# WE2_S_NS register map
Vendor: ARM Ltd.; Series: ARMv8.1-M Mainline; File version: 1.0
CPU: CM55 r1p1, little endian, MPU, FPU, double-precision FPU, DSP, VTOR, 3 interrupt priority bits
Registers are 32-bit, read-write, reset 0x0 unless marked. A register's access mark holds for its fields unless they carry their own. Offsets are from the block's base; [hi:lo] are bit positions; {n}, {i} and the like mark numbered series.

## SYS_ITM
Base 0xE0000000
{0x0+4i} STIM{i} reset 0x2 (i=0..31) — ITM Stimulus Port Registers {i}
0xE00 TER — ITM Trace Enable Register
0xE40 TPR — ITM Trace Privilege Register
0xE80 TCR — ITM Trace Control Register
0xEF0 INT_ITREAD ro — Integration Read Register
0xEF8 INT_ITWRITE wo — Integration Write Register
0xF00 ITCTRL wo — ITM Integration Mode Control Register
0xFBC DEVARCH ro reset 0x47701A01 — ITM CoreSight Device Architecture Register
0xFCC DEVTYPE wo reset 0x43 — ITM CoreSight Device Type Register
0xFD0 PIDR4 ro reset 0x4 — ITM Peripheral identification registers 4
{0xFC0+4i} PIDR{i} ro (i=5..7) — ITM Peripheral identification registers {i}
0xFE0 PIDR0 ro reset 0xD2 — ITM Peripheral identification registers 0
0xFE4 PIDR1 ro reset 0xBD — ITM Peripheral identification registers 1
0xFE8 PIDR2 ro reset 0xB — ITM Peripheral identification registers 2
0xFEC PIDR3 ro — ITM Peripheral identification registers 3
0xFF0 CIDR0 ro reset 0xD — ITM Component identification register 0
0xFF4 CIDR1 ro reset 0x90 — ITM Component identification register 1
0xFF8 CIDR2 ro reset 0x5 — ITM Component identification register 2
0xFFC CIDR3 ro reset 0xB1 — ITM Component identification register 3

## SYS_DWT — Data Watchpoint and Trace (DWT) registers
Base 0xE0001000
0x00 DWT_CTRL — DWT Control Register
0x04 DWT_CYCCNT — DWT Cycle Count Register
0x08 DWT_CPICNT — DWT CPI Count Register
0x0C DWT_EXCCNT — DWT Exception Overhead Count Register
0x10 DWT_SLEEPCNT — DWT Sleep Count Register
0x14 DWT_LSUCNT — DWT LSU Count Register
0x18 DWT_FOLDCNT — DWT Folded-instruction Count Register
0x1C DWT_PCSR ro — DWT Program Counter Sample Register

## SYS_BPU — Direct Cache Access Registers
Base 0xE0002000
0x00 FP_CTRL — Flash Patch Control Register
0x04 FP_REMAP — Flash Patch Remap. This register is not implemented
{0x8+4i} FP_COMP{i} (i=0..7) — Flash Patch Comparator Register {i}

## SYS_NVIC_STIR — Software Interrupt Generation register
Base 0xE000EF00
Same registers: SYS_NVIC_STIR_NS 0xE002EF00
0x00 STIR wo — Software Interrupt Generation register

## SYS_DCB
Base 0xE000EDF0
Same registers: SYS_DCB_NS 0xE002EDF0
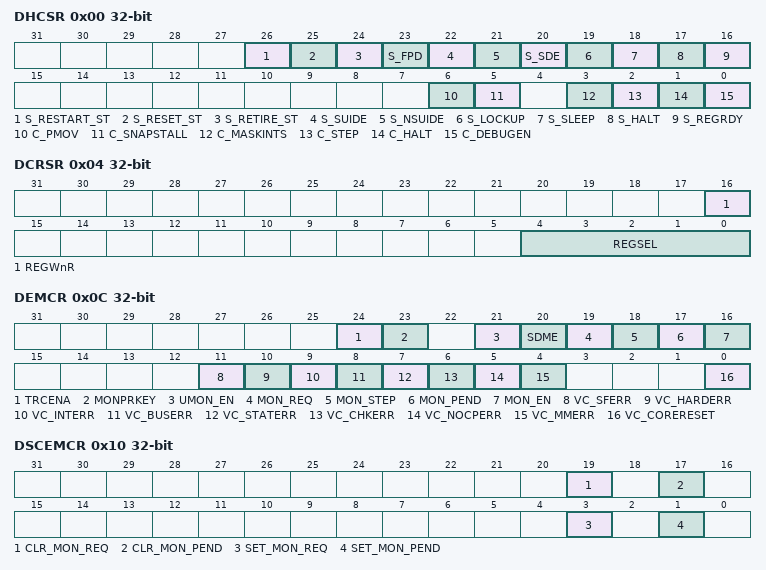
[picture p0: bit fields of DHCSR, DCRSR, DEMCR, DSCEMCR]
0x00 DHCSR — Debug Halting Control and Status Register. Software must write 0xA05F to this field to enable write accesses to bits [15:0], otherwise the processor ignores the write access.
  [26] S_RESTART_ST ro — CoreDebug S_RESTART_ST
  [25] S_RESET_ST ro — CoreDebug S_RESET_ST
  [24] S_RETIRE_ST ro — CoreDebug S_RETIRE_ST
  [23] S_FPD — CoreDebug S_FPD
  [22] S_SUIDE — CoreDebug S_SUIDE
  [21] S_NSUIDE — CoreDebug S_NSUIDE
  [20] S_SDE — CoreDebug S_SDE
  [19] S_LOCKUP ro — CoreDebug S_LOCKUP
  [18] S_SLEEP ro — CoreDebug S_SLEEP
  [17] S_HALT ro — CoreDebug S_HALT
  [16] S_REGRDY ro — CoreDebug S_REGRDY
  [6] C_PMOV — CoreDebug C_PMOV
  [5] C_SNAPSTALL — CoreDebug C_SNAPSTALL
  [3] C_MASKINTS — CoreDebug C_MASKINTS
  [2] C_STEP — CoreDebug C_STEP
  [1] C_HALT — CoreDebug C_HALT
  [0] C_DEBUGEN — CoreDebug C_DEBUGEN
0x04 DCRSR — Debug Core Register Selector Register
  [16] REGWnR — CoreDebug REGWnR
  [4:0] REGSEL — CoreDebug REGSEL
0x08 DCRDR — Debug Core Register Data Register
  [31:0] DBGTMP — CoreDebug Data temporary buffer
0x0C DEMCR — Debug Exception and Monitor Control Register
  [24] TRCENA — CoreDebug TRCENA
  [23] MONPRKEY — CoreDebug MONPRKEY
  [21] UMON_EN — CoreDebug UMON_EN
  [20] SDME — CoreDebug SDME
  [19] MON_REQ — CoreDebug MON_REQ
  [18] MON_STEP — CoreDebug MON_STEP
  [17] MON_PEND — CoreDebug MON_PEND
  [16] MON_EN — CoreDebug MON_EN
  [11] VC_SFERR — CoreDebug VC_SFERR
  [10] VC_HARDERR — CoreDebug VC_HARDERR
  [9] VC_INTERR — CoreDebug VC_INTERR
  [8] VC_BUSERR — CoreDebug VC_BUSERR
  [7] VC_STATERR — CoreDebug VC_STATERR
  [6] VC_CHKERR — CoreDebug VC_CHKERR
  [5] VC_NOCPERR — CoreDebug VC_NOCPERR
  [4] VC_MMERR — CoreDebug VC_MMERR
  [0] VC_CORERESET — CoreDebug VC_CORERESET
0x10 DSCEMCR — Debug Set Clear Exception and Monitor Control Register
  [19] CLR_MON_REQ — CoreDebug CLR_MON_REQ
  [17] CLR_MON_PEND — CoreDebug CLR_MON_PEND
  [3] SET_MON_REQ — CoreDebug SET_MON_REQ
  [1] SET_MON_PEND — CoreDebug SET_MON_PEND
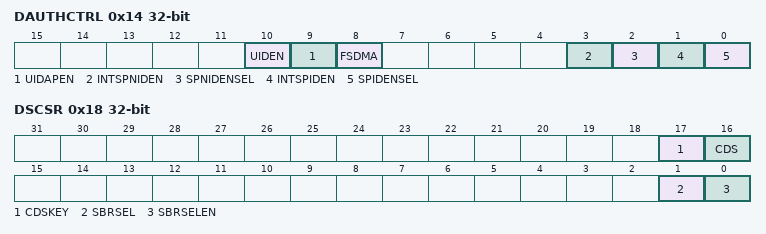
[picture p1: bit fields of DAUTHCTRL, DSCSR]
0x14 DAUTHCTRL — Debug Authentication Control Register
  [10] UIDEN — CoreDebug UIDEN
  [9] UIDAPEN — CoreDebug UIDAPEN
  [8] FSDMA — CoreDebug FSDMA
  [3] INTSPNIDEN — CoreDebug INTSPNIDEN
  [2] SPNIDENSEL — CoreDebug SPNIDENSEL
  [1] INTSPIDEN — CoreDebug INTSPIDEN
  [0] SPIDENSEL — CoreDebug SPIDENSEL
0x18 DSCSR — Debug Security Control and Status Register
  [17] CDSKEY — CoreDebug CDSKEY
  [16] CDS — CoreDebug CDS
  [1] SBRSEL — CoreDebug SBRSEL
  [0] SBRSELEN — CoreDebug SBRSELEN
